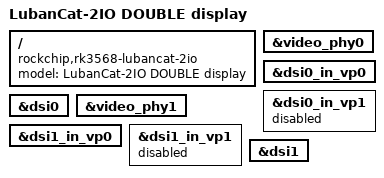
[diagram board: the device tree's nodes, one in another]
// SPDX-License-Identifier: (GPL-2.0+ OR MIT)
/*
 * Copyright (c) 2020 Rockchip Electronics Co., Ltd.
 *
 */

/dts-v1/;

#include "rk3568-lubancat-2io.dtsi"

/ {
	model = "LubanCat-2IO DOUBLE display";
	compatible = "rockchip,rk3568-lubancat-2io", "rockchip,rk3568";
};

// &hdmi {
// 	status = "okay";
// };

// &hdmi_in_vp0 {
// 	status = "okay";
// };

// &hdmi_in_vp1 {
// 	status = "disable";
// };




&video_phy0 {
		status = "okay";
};

&dsi0_in_vp0 {
	status = "okay";
};

&dsi0_in_vp1 {
	status = "disable";
};

&dsi0 {
	status = "okay";
};

// &rockpi_mcu {
// 	status = "okay";
// };

// &rockpi_ft5406 {
// 	status = "okay";
// };

&video_phy1 {
	status = "okay";
};

&dsi1_in_vp0 {
	status = "okay";
};

&dsi1_in_vp1 {
	status = "disable";
};

&dsi1 {
	status = "okay";
};

// &edp_phy {
// 	status = "okay";
// };

// &edp_in_vp0 {
// 	status = "okay";
// };

// &edp_in_vp1 {
// 	status = "disabled";
// };

// &edp {
// 	status = "okay";
// };

// &edp_panel {
// 	status = "okay";
// };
